VERSION ""

NS_ :

BS_:

BU_:

BO_ 1044 m_diag_1: 8 Vector__XXX
 SG_ reg_out : 7|32@0- (0.001,0) [0|0] "" Vector__XXX
 SG_ er : 39|32@0- (0.001,0) [0|0] "" Vector__XXX

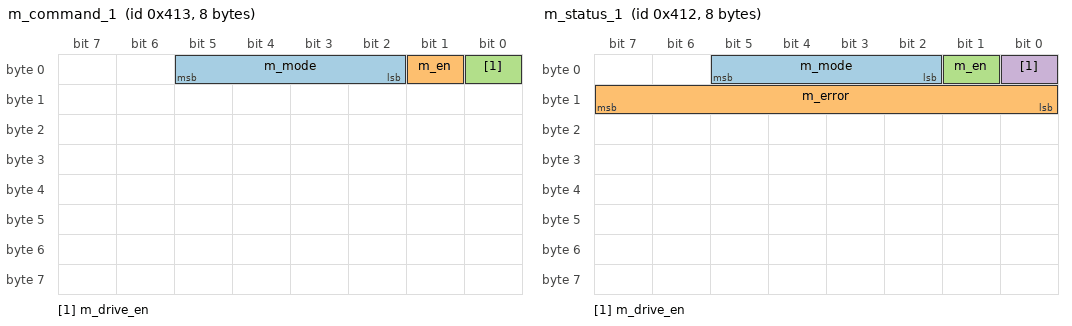
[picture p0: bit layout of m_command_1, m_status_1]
BO_ 1043 m_command_1: 8 Vector__XXX
 SG_ m_mode : 5|4@0+ (1,0) [0|0] "" Vector__XXX
 SG_ m_en : 1|1@1+ (1,0) [0|0] "" Vector__XXX
 SG_ m_drive_en : 0|1@1+ (1,0) [0|0] "" Vector__XXX

BO_ 1042 m_status_1: 8 Vector__XXX
 SG_ m_mode : 5|4@0+ (1,0) [0|0] "" Vector__XXX
 SG_ m_error : 15|8@0+ (1,0) [0|0] "" Vector__XXX
 SG_ m_en : 1|1@1+ (1,0) [0|0] "" Vector__XXX
 SG_ m_drive_en : 0|1@1+ (1,0) [0|0] "" Vector__XXX

BO_ 1041 m_ref_1: 8 Vector__XXX
 SG_ velocity : 39|32@0- (0.001,0) [0|0] "" Vector__XXX
 SG_ position : 7|32@0- (0.001,0) [0|0] "" Vector__XXX

BO_ 1040 m_pos_vel_1: 8 Vector__XXX
 SG_ velocity : 39|32@0- (0.001,0) [0|0] "" Vector__XXX
 SG_ position : 7|32@0- (0.001,0) [0|0] "" Vector__XXX

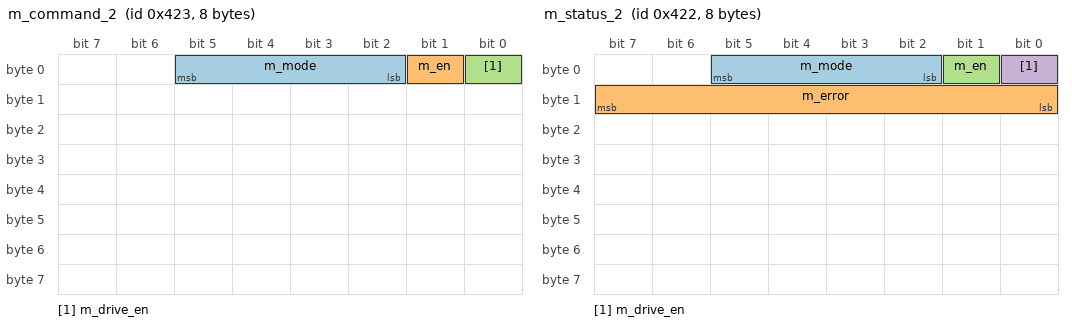
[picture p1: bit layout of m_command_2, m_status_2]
BO_ 1059 m_command_2: 8 Vector__XXX
 SG_ m_mode : 5|4@0+ (1,0) [0|0] "" Vector__XXX
 SG_ m_en : 1|1@1+ (1,0) [0|0] "" Vector__XXX
 SG_ m_drive_en : 0|1@1+ (1,0) [0|0] "" Vector__XXX

BO_ 1058 m_status_2: 8 Vector__XXX
 SG_ m_mode : 5|4@0+ (1,0) [0|0] "" Vector__XXX
 SG_ m_error : 15|8@0+ (1,0) [0|0] "" Vector__XXX
 SG_ m_en : 1|1@1+ (1,0) [0|0] "" Vector__XXX
 SG_ m_drive_en : 0|1@1+ (1,0) [0|0] "" Vector__XXX

BO_ 1057 m_ref_2: 8 Vector__XXX
 SG_ velocity : 39|32@0- (0.001,0) [0|0] "" Vector__XXX
 SG_ position : 7|32@0- (0.001,0) [0|0] "" Vector__XXX

BO_ 1056 m_pos_vel_2: 8 Vector__XXX
 SG_ velocity : 39|32@0- (0.001,0) [0|0] "" Vector__XXX
 SG_ position : 7|32@0- (0.001,0) [0|0] "" Vector__XXX

 BO_ 1060 m_diag_2: 8 Vector__XXX
 SG_ reg_out : 7|32@0- (0.001,0) [0|0] "" Vector__XXX
 SG_ er : 39|32@0- (0.001,0) [0|0] "" Vector__XXX

BA_DEF_ BO_  "CANFD_BRS" ENUM  "0","1";
BA_DEF_  "DBName" STRING ;
BA_DEF_  "BusType" STRING ;
BA_DEF_ BO_  "VFrameFormat" ENUM  "StandardCAN","ExtendedCAN","reserved","reserved","reserved","reserved","reserved","reserved","reserved","reserved","reserved","reserved","reserved","reserved","StandardCAN_FD","ExtendedCAN_FD";
BA_DEF_DEF_  "CANFD_BRS" "1";
BA_DEF_DEF_  "DBName" "";
BA_DEF_DEF_  "BusType" "";
BA_DEF_DEF_  "VFrameFormat" "StandardCAN";
BA_ "BusType" "CAN";
BA_ "DBName" "Motor_Control_v2a";
